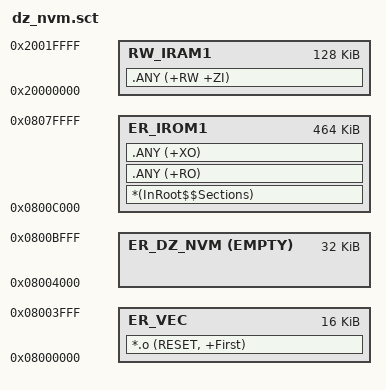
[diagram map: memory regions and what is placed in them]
; 由 tools/gen_ide_nvm.py 按 board.yaml mcu.nvm_kb=32 生成，勿手改。【未测】未在 Keil 里编译过。
; 保存区 ER_DZ_NVM 0x08004000 长 0x00008000：EMPTY 域，不进 hex/axf 的加载数据，下载不会擦掉已存参数。
LR_VEC 0x08000000 0x00004000 {
  ER_VEC 0x08000000 0x00004000 {
   *.o (RESET, +First)
  }
}
LR_DZ_NVM 0x08004000 0x00008000 {
  ER_DZ_NVM 0x08004000 EMPTY 0x00008000 { }
}
LR_IROM1 0x0800C000 0x00074000 {
  ER_IROM1 0x0800C000 0x00074000 {
   *(InRoot$$Sections)
   .ANY (+RO)
   .ANY (+XO)
  }
  RW_IRAM1 0x20000000 0x00020000 {
   .ANY (+RW +ZI)
  }
}
